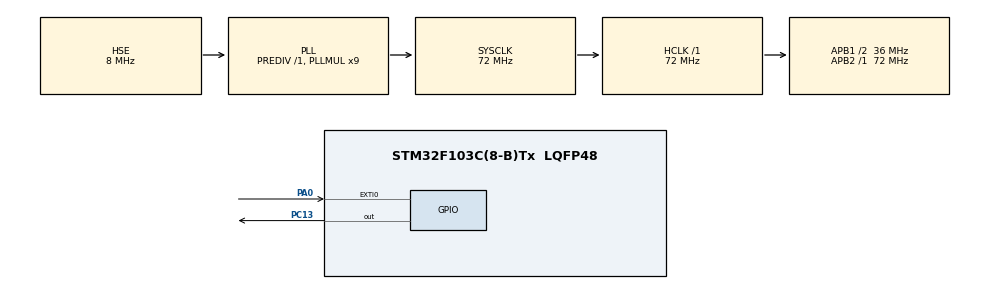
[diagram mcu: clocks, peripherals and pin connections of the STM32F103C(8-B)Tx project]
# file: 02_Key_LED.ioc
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Mcu.Family=STM32F1
Mcu.Name=STM32F103C(8-B)Tx
Mcu.Package=LQFP48
NVIC.EXTI0_IRQn=true\:1\:0\:true\:false\:true\:true\:true\:true
NVIC.PriorityGroup=NVIC_PRIORITYGROUP_4
NVIC.TIM2_IRQn=true\:2\:0\:true\:false\:true\:true\:true\:true
PA0-WKUP.GPIO_ModeDefaultEXTI=GPIO_MODE_IT_FALLING
PA0-WKUP.GPIO_PuPd=GPIO_PULLUP
PA0-WKUP.Signal=GPXTI0
PA13.Mode=Serial_Wire
PA13.Signal=SYS_JTMS-SWDIO
PA14.Mode=Serial_Wire
PA14.Signal=SYS_JTCK-SWCLK
PC13-TAMPER-RTC.Signal=GPIO_Output
PD0-OSC_IN.Mode=HSE-External-Oscillator
PD0-OSC_IN.Signal=RCC_OSC_IN
PD1-OSC_OUT.Mode=HSE-External-Oscillator
PD1-OSC_OUT.Signal=RCC_OSC_OUT
ProjectManager.HeapSize=0x200
ProjectManager.StackSize=0x400
ProjectManager.TargetToolchain=Makefile
RCC.AHBFreq_Value=72000000
RCC.APB1CLKDivider=RCC_HCLK_DIV2
RCC.APB1Freq_Value=36000000
RCC.APB1TimFreq_Value=72000000
RCC.APB2Freq_Value=72000000
RCC.APB2TimFreq_Value=72000000
RCC.HCLKFreq_Value=72000000
RCC.PLLMUL=RCC_PLL_MUL9
RCC.PLLSourceVirtual=RCC_PLLSOURCE_HSE
RCC.SYSCLKFreq_VALUE=72000000
RCC.SYSCLKSource=RCC_SYSCLKSOURCE_PLLCLK
RCC.USBFreq_Value=72000000
TIM2.Period=999
TIM2.Prescaler=71
VP_TIM2_VS_ClockSourceINT.Mode=Internal
board=custom

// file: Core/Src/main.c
/* USER CODE BEGIN Header */
/**
  ******************************************************************************
  * @file           : main.c
  * @brief          : Main program body
  ******************************************************************************
  * @attention
  *
  * Copyright (c) 2026 STMicroelectronics.
  * All rights reserved.
  *
  * This software is licensed under terms that can be found in the LICENSE file
  * in the root directory of this software component.
  * If no LICENSE file comes with this software, it is provided AS-IS.
  *
  ******************************************************************************
  */
/* USER CODE END Header */
#include "main.h"

TIM_HandleTypeDef htim2;

/* USER CODE BEGIN PV */
volatile uint8_t key_pressed = 0;    // 标记按键是否按下
volatile uint8_t led_state = 0;      // 当前档位 (0, 1, 2)
volatile uint16_t led_delay_ms = 500;// 默认500ms（半周期，即1秒闪一下）
/* USER CODE END PV */

void SystemClock_Config(void);
static void MX_GPIO_Init(void);
static void MX_TIM2_Init(void);

int main(void)
{

  /* MCU Configuration--------------------------------------------------------*/

  /* Reset of all peripherals, Initializes the Flash interface and the Systick. */
  HAL_Init();

  /* Configure the system clock */
  SystemClock_Config();

  /* Initialize all configured peripherals */
  MX_GPIO_Init();
  MX_TIM2_Init();
  /* USER CODE BEGIN 2 */
HAL_TIM_Base_Start_IT(&htim2); // 启动定时器2，让闹钟开始走
  /* USER CODE END 2 */

  /* Infinite loop */
  while (1)
  {

    /* USER CODE BEGIN 3 */
    if (key_pressed == 1) // 如果中断记录到按键被按下
{
    HAL_Delay(20); // 延迟20ms，躲避按键抖动
    if (HAL_GPIO_ReadPin(GPIOA, GPIO_PIN_0) == GPIO_PIN_RESET) // 再次确认确实按下了
    {
        led_state = (led_state + 1) % 3; // 切换档位 0->1, 1->2, 2->0
        if (led_state == 0) led_delay_ms = 500;       // 1秒周期
        else if (led_state == 1) led_delay_ms = 1000; // 2秒周期
        else if (led_state == 2) led_delay_ms = 250;  // 0.5秒周期
    }
    while (HAL_GPIO_ReadPin(GPIOA, GPIO_PIN_0) == GPIO_PIN_RESET); // 死等松手（防长按连续切换）
    key_pressed = 0; // 清除标志，准备下一次
}
  }
  /* USER CODE END 3 */
}

void SystemClock_Config(void)
{
  RCC_OscInitTypeDef RCC_OscInitStruct = {0};
  RCC_ClkInitTypeDef RCC_ClkInitStruct = {0};

  /** Initializes the RCC Oscillators according to the specified parameters
  * in the RCC_OscInitTypeDef structure.
  */
  RCC_OscInitStruct.OscillatorType = RCC_OSCILLATORTYPE_HSE;
  RCC_OscInitStruct.HSEState = RCC_HSE_ON;
  RCC_OscInitStruct.HSEPredivValue = RCC_HSE_PREDIV_DIV1;
  RCC_OscInitStruct.HSIState = RCC_HSI_ON;
  RCC_OscInitStruct.PLL.PLLState = RCC_PLL_ON;
  RCC_OscInitStruct.PLL.PLLSource = RCC_PLLSOURCE_HSE;
  RCC_OscInitStruct.PLL.PLLMUL = RCC_PLL_MUL9;
  if (HAL_RCC_OscConfig(&RCC_OscInitStruct) != HAL_OK)
  {
    Error_Handler();
  }

  /** Initializes the CPU, AHB and APB buses clocks
  */
  RCC_ClkInitStruct.ClockType = RCC_CLOCKTYPE_HCLK|RCC_CLOCKTYPE_SYSCLK
                              |RCC_CLOCKTYPE_PCLK1|RCC_CLOCKTYPE_PCLK2;
  RCC_ClkInitStruct.SYSCLKSource = RCC_SYSCLKSOURCE_PLLCLK;
  RCC_ClkInitStruct.AHBCLKDivider = RCC_SYSCLK_DIV1;
  RCC_ClkInitStruct.APB1CLKDivider = RCC_HCLK_DIV2;
  RCC_ClkInitStruct.APB2CLKDivider = RCC_HCLK_DIV1;

  if (HAL_RCC_ClockConfig(&RCC_ClkInitStruct, FLASH_LATENCY_2) != HAL_OK)
  {
    Error_Handler();
  }
}

static void MX_TIM2_Init(void)
{

  TIM_ClockConfigTypeDef sClockSourceConfig = {0};
  TIM_MasterConfigTypeDef sMasterConfig = {0};

  htim2.Instance = TIM2;
  htim2.Init.Prescaler = 71;
  htim2.Init.CounterMode = TIM_COUNTERMODE_UP;
  htim2.Init.Period = 999;
  htim2.Init.ClockDivision = TIM_CLOCKDIVISION_DIV1;
  htim2.Init.AutoReloadPreload = TIM_AUTORELOAD_PRELOAD_DISABLE;
  if (HAL_TIM_Base_Init(&htim2) != HAL_OK)
  {
    Error_Handler();
  }
  sClockSourceConfig.ClockSource = TIM_CLOCKSOURCE_INTERNAL;
  if (HAL_TIM_ConfigClockSource(&htim2, &sClockSourceConfig) != HAL_OK)
  {
    Error_Handler();
  }
  sMasterConfig.MasterOutputTrigger = TIM_TRGO_RESET;
  sMasterConfig.MasterSlaveMode = TIM_MASTERSLAVEMODE_DISABLE;
  if (HAL_TIMEx_MasterConfigSynchronization(&htim2, &sMasterConfig) != HAL_OK)
  {
    Error_Handler();
  }

}

static void MX_GPIO_Init(void)
{
  GPIO_InitTypeDef GPIO_InitStruct = {0};

  /* GPIO Ports Clock Enable */
  __HAL_RCC_GPIOC_CLK_ENABLE();
  __HAL_RCC_GPIOD_CLK_ENABLE();
  __HAL_RCC_GPIOA_CLK_ENABLE();

  /*Configure GPIO pin Output Level */
  HAL_GPIO_WritePin(GPIOC, GPIO_PIN_13, GPIO_PIN_RESET);

  /*Configure GPIO pin : PC13 */
  GPIO_InitStruct.Pin = GPIO_PIN_13;
  GPIO_InitStruct.Mode = GPIO_MODE_OUTPUT_PP;
  GPIO_InitStruct.Pull = GPIO_NOPULL;
  GPIO_InitStruct.Speed = GPIO_SPEED_FREQ_LOW;
  HAL_GPIO_Init(GPIOC, &GPIO_InitStruct);

  /*Configure GPIO pin : PA0 */
  GPIO_InitStruct.Pin = GPIO_PIN_0;
  GPIO_InitStruct.Mode = GPIO_MODE_IT_FALLING;
  GPIO_InitStruct.Pull = GPIO_PULLUP;
  HAL_GPIO_Init(GPIOA, &GPIO_InitStruct);

  /* EXTI interrupt init*/
  HAL_NVIC_SetPriority(EXTI0_IRQn, 1, 0);
  HAL_NVIC_EnableIRQ(EXTI0_IRQn);

}

/* USER CODE BEGIN 4 */
// 定时器中断：控制灯闪烁
void HAL_TIM_PeriodElapsedCallback(TIM_HandleTypeDef *htim)
{
    if (htim->Instance == TIM2) // 如果是TIM2的闹钟响了
    {
        static uint16_t count = 0; // 计数变量
        count++;
        if (count >= led_delay_ms) // 如果计数达到设定时间
        {
            count = 0;
            HAL_GPIO_TogglePin(GPIOC, GPIO_PIN_13); // 翻转灯的状态！
        }
    }
}

// 按键中断：记录按键按下的瞬间
void HAL_GPIO_EXTI_Callback(uint16_t GPIO_Pin)
{
    if (GPIO_Pin == GPIO_PIN_0) // 如果是PA0触发的
    {
        key_pressed = 1; // 仅仅记录标志，立刻退出
    }
}
/* USER CODE END 4 */

void Error_Handler(void)
{
  __disable_irq();
  while (1)
  {
  }
}
